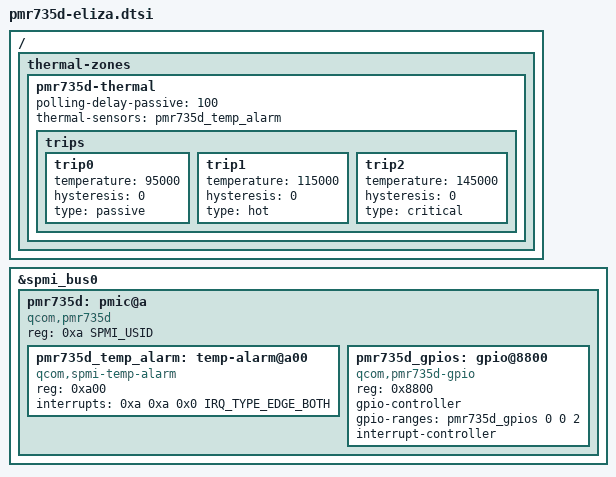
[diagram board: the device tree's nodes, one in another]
// SPDX-License-Identifier: BSD-3-Clause
/*
 * Copyright (c) 2026 Qualcomm Innovation Center, Inc. All rights reserved.
 */

#include <dt-bindings/interrupt-controller/irq.h>
#include <dt-bindings/spmi/spmi.h>

/ {
	thermal-zones {
		pmr735d-thermal {
			polling-delay-passive = <100>;

			thermal-sensors = <&pmr735d_temp_alarm>;

			trips {
				trip0 {
					temperature = <95000>;
					hysteresis = <0>;
					type = "passive";
				};

				trip1 {
					temperature = <115000>;
					hysteresis = <0>;
					type = "hot";
				};

				trip2 {
					temperature = <145000>;
					hysteresis = <0>;
					type = "critical";
				};
			};
		};
	};
};

&spmi_bus0 {
	pmr735d: pmic@a {
		compatible = "qcom,pmr735d", "qcom,spmi-pmic";
		reg = <0xa SPMI_USID>;
		#address-cells = <1>;
		#size-cells = <0>;

		pmr735d_temp_alarm: temp-alarm@a00 {
			compatible = "qcom,spmi-temp-alarm";
			reg = <0xa00>;
			interrupts = <0xa 0xa 0x0 IRQ_TYPE_EDGE_BOTH>;
			#thermal-sensor-cells = <0>;
		};

		pmr735d_gpios: gpio@8800 {
			compatible = "qcom,pmr735d-gpio", "qcom,spmi-gpio";
			reg = <0x8800>;
			gpio-controller;
			gpio-ranges = <&pmr735d_gpios 0 0 2>;
			#gpio-cells = <2>;
			interrupt-controller;
			#interrupt-cells = <2>;
		};
	};
};
